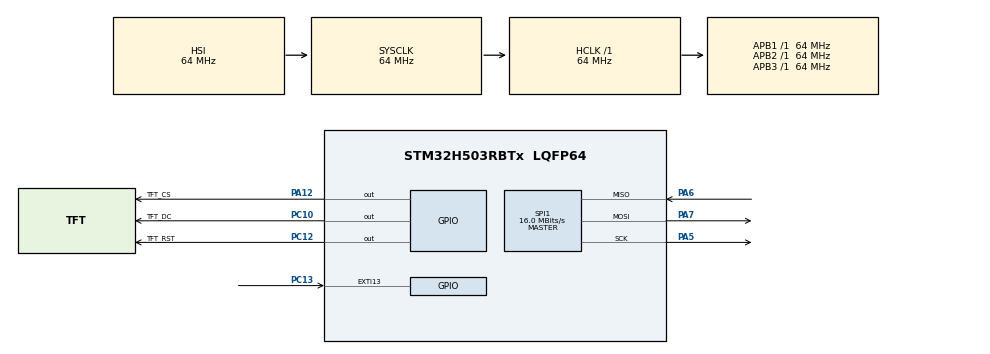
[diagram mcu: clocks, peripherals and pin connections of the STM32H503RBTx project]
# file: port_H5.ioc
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BOOTPATH.BootPathName=LEGACY
BOOTPATH.UserSelectedBootPath=LEGACY
Mcu.Family=STM32H5
Mcu.Name=STM32H503RBTx
Mcu.Package=LQFP64
NUCLEO-H503RB.BUTTON=1
NUCLEO-H503RB.LD2=true
NUCLEO-H503RB.VCP=true
NVIC.EXTI13_IRQn=true\:0\:0\:false\:false\:true\:false\:true\:true
NVIC.PriorityGroup=NVIC_PRIORITYGROUP_4
PA12.GPIO_Label=TFT_CS
PA12.PinState=GPIO_PIN_SET
PA12.Signal=GPIO_Output
PA3.Signal=USART3_RX
PA4.Signal=USART3_TX
PA5.Mode=Full_Duplex_Master
PA5.Signal=SPI1_SCK
PA6.Mode=Full_Duplex_Master
PA6.Signal=SPI1_MISO
PA7.Mode=Full_Duplex_Master
PA7.Signal=SPI1_MOSI
PC10.GPIO_Label=TFT_DC
PC10.Signal=GPIO_Output
PC12.GPIO_Label=TFT_RST
PC12.PinState=GPIO_PIN_SET
PC12.Signal=GPIO_Output
PC13.Signal=GPXTI13
PH0-OSC_IN(PH0).Mode=HSE-External-Oscillator
PH0-OSC_IN(PH0).Signal=RCC_OSC_IN
PH1-OSC_OUT(PH1).Mode=HSE-External-Oscillator
PH1-OSC_OUT(PH1).Signal=RCC_OSC_OUT
ProjectManager.HeapSize=0x200
ProjectManager.StackSize=0x400
ProjectManager.TargetToolchain=STM32CubeIDE
RCC.ADCFreq_Value=64000000
RCC.AHBFreq_Value=64000000
RCC.APB1Freq_Value=64000000
RCC.APB1TimFreq_Value=64000000
RCC.APB2Freq_Value=64000000
RCC.APB2TimFreq_Value=64000000
RCC.APB3Freq_Value=64000000
RCC.CSI_VALUE=4000000
RCC.CortexFreq_Value=64000000
RCC.EPOD_VALUE=4000000
RCC.HCLKFreq_Value=64000000
RCC.HSE_VALUE=24000000
RCC.HSI48_VALUE=48000000
RCC.HSIDiv=RCC_HSI_DIV1
RCC.HSI_VALUE=64000000
RCC.LSE_VALUE=32768
RCC.LSIRC_VALUE=32000
RCC.PLLN=32
RCC.SYSCLKFreq_VALUE=64000000
RCC.USBFreq_Value=48000000
RCC.VCOOutputFreq_Value=128000000
RTC.Hours=3
RTC.Minutes=30
RTC.Seconds=30
SPI1.BaudRatePrescaler=SPI_BAUDRATEPRESCALER_4
SPI1.CalculateBaudRate=16.0 MBits/s
SPI1.DataSize=SPI_DATASIZE_8BIT
SPI1.Direction=SPI_DIRECTION_2LINES
SPI1.Mode=SPI_MODE_MASTER
SPI1.VirtualType=VM_MASTER
VP_BOOTPATH_VS_BOOTPATH.Mode=BP_Activate
VP_CORTEX_M33_NS_VS_Hclk.Mode=Hclk_Mode
VP_ICACHE_VS_ICACHE.Mode=DirectMappedCache
VP_MEMORYMAP_VS_MEMORYMAP.Mode=CurAppReg
VP_NUCLEO-H503RB_VS_BSP_COMMON.Mode=COMMON
VP_PWR_VS_DBSignals.Mode=DisableDeadBatterySignals
VP_PWR_VS_LPOM.Mode=PowerOptimisation
VP_PWR_VS_SECSignals.Mode=Security/Privilege
VP_RTC_VS_RTC_Activate.Mode=RTC_Enabled
VP_RTC_VS_RTC_Calendar.Mode=RTC_Calendar
board=NUCLEO-H503RB

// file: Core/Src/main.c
/* USER CODE BEGIN Header */
/**
  ******************************************************************************
  * @file           : main.c
  * @brief          : Main program body
  ******************************************************************************
  * @attention
  *
  * Copyright (c) 2024 STMicroelectronics.
  * All rights reserved.
  *
  * This software is licensed under terms that can be found in the LICENSE file
  * in the root directory of this software component.
  * If no LICENSE file comes with this software, it is provided AS-IS.
  *
  ******************************************************************************
  */
/* USER CODE END Header */
#include "main.h"

/* USER CODE BEGIN Includes */
#include "ILI9486.h"
#include "stdio.h"

volatile uint8_t SPI1_TX_completed_flag = 1;
/* USER CODE END Includes */

COM_InitTypeDef BspCOMInit;

RTC_HandleTypeDef hrtc;

SPI_HandleTypeDef hspi1;

void SystemClock_Config(void);
static void MX_GPIO_Init(void);
static void MX_RTC_Init(void);
static void MX_ICACHE_Init(void);
static void MX_SPI1_Init(void);

/* USER CODE BEGIN 0 */
void HAL_SPI_TxCpltCallback(SPI_HandleTypeDef *hspi) {
  SPI1_TX_completed_flag = 1;
}
/* USER CODE END 0 */

int main(void)
{

  /* MCU Configuration--------------------------------------------------------*/

  /* Reset of all peripherals, Initializes the Flash interface and the Systick. */
  HAL_Init();

  /* Configure the system clock */
  SystemClock_Config();

  /* Initialize all configured peripherals */
  MX_GPIO_Init();
  MX_RTC_Init();
  MX_ICACHE_Init();
  MX_SPI1_Init();

  /* Initialize led */
  BSP_LED_Init(LED_GREEN);

  /* Initialize USER push-button, will be used to trigger an interrupt each time it's pressed.*/
  BSP_PB_Init(BUTTON_USER, BUTTON_MODE_EXTI);

  /* Initialize COM1 port (115200, 8 bits (7-bit data + 1 stop bit), no parity */
  BspCOMInit.BaudRate   = 115200;
  BspCOMInit.WordLength = COM_WORDLENGTH_8B;
  BspCOMInit.StopBits   = COM_STOPBITS_1;
  BspCOMInit.Parity     = COM_PARITY_NONE;
  BspCOMInit.HwFlowCtl  = COM_HWCONTROL_NONE;
  if (BSP_COM_Init(COM1, &BspCOMInit) != BSP_ERROR_NONE)
  {
    Error_Handler();
  }

  /* Infinite loop */
  /* USER CODE BEGIN WHILE */

  ILI9488_Init();
  setRotation(1);
  fillScreen(ILI9488_RED);
  while (1)
  {
	  fillScreen(ILI9488_RED);
	  fillScreen(ILI9488_NAVY);
    /* USER CODE END WHILE */

  }
}

void SystemClock_Config(void)
{
  RCC_OscInitTypeDef RCC_OscInitStruct = {0};
  RCC_ClkInitTypeDef RCC_ClkInitStruct = {0};

  /** Configure the main internal regulator output voltage
  */
  __HAL_PWR_VOLTAGESCALING_CONFIG(PWR_REGULATOR_VOLTAGE_SCALE3);

  while(!__HAL_PWR_GET_FLAG(PWR_FLAG_VOSRDY)) {}

  /** Initializes the RCC Oscillators according to the specified parameters
  * in the RCC_OscInitTypeDef structure.
  */
  RCC_OscInitStruct.OscillatorType = RCC_OSCILLATORTYPE_HSI|RCC_OSCILLATORTYPE_LSI
                              |RCC_OSCILLATORTYPE_CSI;
  RCC_OscInitStruct.HSIState = RCC_HSI_ON;
  RCC_OscInitStruct.HSIDiv = RCC_HSI_DIV1;
  RCC_OscInitStruct.HSICalibrationValue = RCC_HSICALIBRATION_DEFAULT;
  RCC_OscInitStruct.LSIState = RCC_LSI_ON;
  RCC_OscInitStruct.CSIState = RCC_CSI_ON;
  RCC_OscInitStruct.CSICalibrationValue = RCC_CSICALIBRATION_DEFAULT;
  RCC_OscInitStruct.PLL.PLLState = RCC_PLL_ON;
  RCC_OscInitStruct.PLL.PLLSource = RCC_PLL1_SOURCE_CSI;
  RCC_OscInitStruct.PLL.PLLM = 1;
  RCC_OscInitStruct.PLL.PLLN = 32;
  RCC_OscInitStruct.PLL.PLLP = 2;
  RCC_OscInitStruct.PLL.PLLQ = 2;
  RCC_OscInitStruct.PLL.PLLR = 2;
  RCC_OscInitStruct.PLL.PLLRGE = RCC_PLL1_VCIRANGE_2;
  RCC_OscInitStruct.PLL.PLLVCOSEL = RCC_PLL1_VCORANGE_WIDE;
  RCC_OscInitStruct.PLL.PLLFRACN = 0;
  if (HAL_RCC_OscConfig(&RCC_OscInitStruct) != HAL_OK)
  {
    Error_Handler();
  }

  /** Initializes the CPU, AHB and APB buses clocks
  */
  RCC_ClkInitStruct.ClockType = RCC_CLOCKTYPE_HCLK|RCC_CLOCKTYPE_SYSCLK
                              |RCC_CLOCKTYPE_PCLK1|RCC_CLOCKTYPE_PCLK2
                              |RCC_CLOCKTYPE_PCLK3;
  RCC_ClkInitStruct.SYSCLKSource = RCC_SYSCLKSOURCE_HSI;
  RCC_ClkInitStruct.AHBCLKDivider = RCC_SYSCLK_DIV1;
  RCC_ClkInitStruct.APB1CLKDivider = RCC_HCLK_DIV1;
  RCC_ClkInitStruct.APB2CLKDivider = RCC_HCLK_DIV1;
  RCC_ClkInitStruct.APB3CLKDivider = RCC_HCLK_DIV1;

  if (HAL_RCC_ClockConfig(&RCC_ClkInitStruct, FLASH_LATENCY_3) != HAL_OK)
  {
    Error_Handler();
  }

  /** Configure the programming delay
  */
  __HAL_FLASH_SET_PROGRAM_DELAY(FLASH_PROGRAMMING_DELAY_1);
}

static void MX_ICACHE_Init(void)
{

  /** Enable instruction cache in 1-way (direct mapped cache)
  */
  if (HAL_ICACHE_ConfigAssociativityMode(ICACHE_1WAY) != HAL_OK)
  {
    Error_Handler();
  }
  if (HAL_ICACHE_Enable() != HAL_OK)
  {
    Error_Handler();
  }

}

static void MX_RTC_Init(void)
{

  RTC_PrivilegeStateTypeDef privilegeState = {0};
  RTC_TimeTypeDef sTime = {0};
  RTC_DateTypeDef sDate = {0};

  /** Initialize RTC Only
  */
  hrtc.Instance = RTC;
  hrtc.Init.HourFormat = RTC_HOURFORMAT_24;
  hrtc.Init.AsynchPrediv = 127;
  hrtc.Init.SynchPrediv = 255;
  hrtc.Init.OutPut = RTC_OUTPUT_DISABLE;
  hrtc.Init.OutPutRemap = RTC_OUTPUT_REMAP_NONE;
  hrtc.Init.OutPutPolarity = RTC_OUTPUT_POLARITY_HIGH;
  hrtc.Init.OutPutType = RTC_OUTPUT_TYPE_OPENDRAIN;
  hrtc.Init.OutPutPullUp = RTC_OUTPUT_PULLUP_NONE;
  hrtc.Init.BinMode = RTC_BINARY_NONE;
  if (HAL_RTC_Init(&hrtc) != HAL_OK)
  {
    Error_Handler();
  }
  privilegeState.rtcPrivilegeFull = RTC_PRIVILEGE_FULL_NO;
  privilegeState.backupRegisterPrivZone = RTC_PRIVILEGE_BKUP_ZONE_NONE;
  privilegeState.backupRegisterStartZone2 = RTC_BKP_DR0;
  privilegeState.backupRegisterStartZone3 = RTC_BKP_DR0;
  if (HAL_RTCEx_PrivilegeModeSet(&hrtc, &privilegeState) != HAL_OK)
  {
    Error_Handler();
  }

  /** Initialize RTC and set the Time and Date
  */
  sTime.Hours = 0x3;
  sTime.Minutes = 0x30;
  sTime.Seconds = 0x30;
  sTime.DayLightSaving = RTC_DAYLIGHTSAVING_NONE;
  sTime.StoreOperation = RTC_STOREOPERATION_RESET;
  if (HAL_RTC_SetTime(&hrtc, &sTime, RTC_FORMAT_BCD) != HAL_OK)
  {
    Error_Handler();
  }
  sDate.WeekDay = RTC_WEEKDAY_MONDAY;
  sDate.Month = RTC_MONTH_JANUARY;
  sDate.Date = 0x1;
  sDate.Year = 0x0;

  if (HAL_RTC_SetDate(&hrtc, &sDate, RTC_FORMAT_BCD) != HAL_OK)
  {
    Error_Handler();
  }

}

static void MX_SPI1_Init(void)
{

  /* SPI1 parameter configuration*/
  hspi1.Instance = SPI1;
  hspi1.Init.Mode = SPI_MODE_MASTER;
  hspi1.Init.Direction = SPI_DIRECTION_2LINES;
  hspi1.Init.DataSize = SPI_DATASIZE_8BIT;
  hspi1.Init.CLKPolarity = SPI_POLARITY_LOW;
  hspi1.Init.CLKPhase = SPI_PHASE_1EDGE;
  hspi1.Init.NSS = SPI_NSS_SOFT;
  hspi1.Init.BaudRatePrescaler = SPI_BAUDRATEPRESCALER_4;
  hspi1.Init.FirstBit = SPI_FIRSTBIT_MSB;
  hspi1.Init.TIMode = SPI_TIMODE_DISABLE;
  hspi1.Init.CRCCalculation = SPI_CRCCALCULATION_DISABLE;
  hspi1.Init.CRCPolynomial = 0x7;
  hspi1.Init.NSSPMode = SPI_NSS_PULSE_ENABLE;
  hspi1.Init.NSSPolarity = SPI_NSS_POLARITY_LOW;
  hspi1.Init.FifoThreshold = SPI_FIFO_THRESHOLD_01DATA;
  hspi1.Init.MasterSSIdleness = SPI_MASTER_SS_IDLENESS_00CYCLE;
  hspi1.Init.MasterInterDataIdleness = SPI_MASTER_INTERDATA_IDLENESS_00CYCLE;
  hspi1.Init.MasterReceiverAutoSusp = SPI_MASTER_RX_AUTOSUSP_DISABLE;
  hspi1.Init.MasterKeepIOState = SPI_MASTER_KEEP_IO_STATE_DISABLE;
  hspi1.Init.IOSwap = SPI_IO_SWAP_DISABLE;
  hspi1.Init.ReadyMasterManagement = SPI_RDY_MASTER_MANAGEMENT_INTERNALLY;
  hspi1.Init.ReadyPolarity = SPI_RDY_POLARITY_HIGH;
  if (HAL_SPI_Init(&hspi1) != HAL_OK)
  {
    Error_Handler();
  }

}

static void MX_GPIO_Init(void)
{
  GPIO_InitTypeDef GPIO_InitStruct = {0};

  /* GPIO Ports Clock Enable */
  __HAL_RCC_GPIOH_CLK_ENABLE();
  __HAL_RCC_GPIOA_CLK_ENABLE();
  __HAL_RCC_GPIOC_CLK_ENABLE();

  /*Configure GPIO pin Output Level */
  HAL_GPIO_WritePin(TFT_CS_GPIO_Port, TFT_CS_Pin, GPIO_PIN_SET);

  /*Configure GPIO pin Output Level */
  HAL_GPIO_WritePin(TFT_DC_GPIO_Port, TFT_DC_Pin, GPIO_PIN_RESET);

  /*Configure GPIO pin Output Level */
  HAL_GPIO_WritePin(TFT_RST_GPIO_Port, TFT_RST_Pin, GPIO_PIN_SET);

  /*Configure GPIO pin : TFT_CS_Pin */
  GPIO_InitStruct.Pin = TFT_CS_Pin;
  GPIO_InitStruct.Mode = GPIO_MODE_OUTPUT_PP;
  GPIO_InitStruct.Pull = GPIO_NOPULL;
  GPIO_InitStruct.Speed = GPIO_SPEED_FREQ_LOW;
  HAL_GPIO_Init(TFT_CS_GPIO_Port, &GPIO_InitStruct);

  /*Configure GPIO pins : TFT_DC_Pin TFT_RST_Pin */
  GPIO_InitStruct.Pin = TFT_DC_Pin|TFT_RST_Pin;
  GPIO_InitStruct.Mode = GPIO_MODE_OUTPUT_PP;
  GPIO_InitStruct.Pull = GPIO_NOPULL;
  GPIO_InitStruct.Speed = GPIO_SPEED_FREQ_LOW;
  HAL_GPIO_Init(GPIOC, &GPIO_InitStruct);

}

void Error_Handler(void)
{
  __disable_irq();
  while (1)
  {
  }
}
